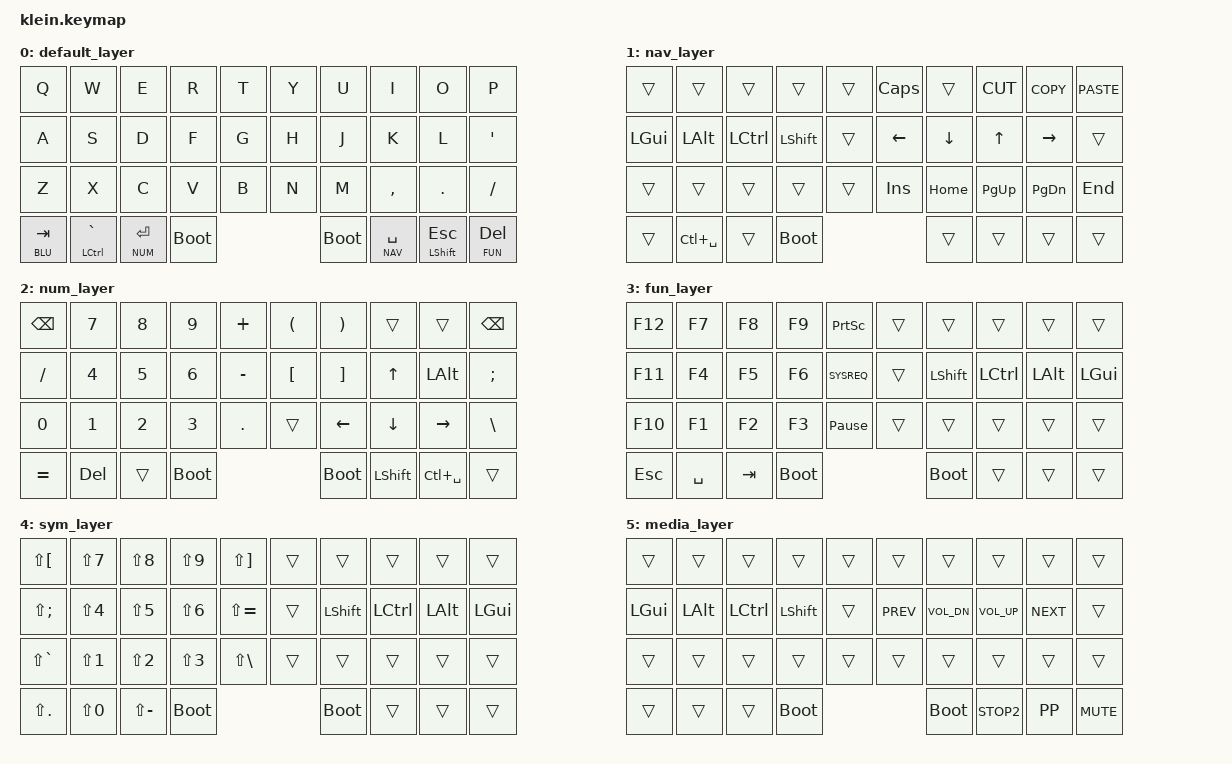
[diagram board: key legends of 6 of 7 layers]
/*
 * Copyright (c) 2020 The ZMK Contributors
 *
 * SPDX-License-Identifier: MIT
 */


#include <behaviors.dtsi>
#include <dt-bindings/zmk/keys.h>
#include <dt-bindings/zmk/bt.h>
#include <dt-bindings/zmk/outputs.h>

#define BASE 0
#define NAV  1
#define NUM  2
#define FUN  3
#define SYM  4
#define MEDIA  5
#define BLU 6

&mt {
  tapping-term-ms = <180>;
};


/ {
    keymap {
        compatible = "zmk,keymap";

        default_layer {
//          ------------------------------------------------------------------------------------------------------------
//          |  Q  |  W  |  E   |  R   |  T   |                                           |  Y   |  U    |  I    |  O   |   P   |
//          |  A  |  S  |  D   |  F   |  G   |                                           |  H   |  J    |  K    |  L   |   '   |
//          |  Z  |  X  |  C   |  V   |  B   |                                           |  N   |  M    |  ,    |  .   |   /   |
//                      | ESC  | SPC |  TAB | BOOTLOADER |                         | MUTE | RET | BKSP | DEL |

            bindings = <
&kp Q          &kp W          &kp E          &kp R          &kp T               &kp Y          &kp U          &kp I          &kp O          &kp P
&kp A          &kp S          &kp D          &kp F          &kp G               &kp H          &kp J            &kp K         &kp L          &kp SQT
&kp Z          &kp X          &kp C          &kp V          &kp B               &kp N          &kp M          &kp COMMA      &kp DOT        &kp FSLH
&lt BLU TAB &mt LCTRL GRAVE  &lt NUM ENTER &bootloader                                       &bootloader      &lt NAV SPACE  &mt LSHFT ESC  &lt FUN DEL
            >;
        sensor-bindings = <&inc_dec_kp C_VOL_DN C_VOL_UP &inc_dec_kp UP DOWN>;
        };

        nav_layer {

            bindings = <
&trans         &trans         &trans         &trans         &trans              &kp CAPSLOCK   &trans         &kp K_CUT      &kp K_COPY     &kp K_PASTE
&kp LGUI       &kp LALT       &kp LCTRL      &kp LSHFT      &trans              &kp LEFT       &kp DOWN       &kp UP         &kp RIGHT      &trans
&trans         &trans         &trans         &trans         &trans              &kp INSERT     &kp HOME       &kp PG_UP      &kp PG_DN      &kp END
&trans         &kp LC(SPACE)      &trans         &bootloader                                       &trans     &trans       &trans      &trans
            >;
        sensor-bindings = <&inc_dec_kp C_VOL_DN C_VOL_UP>;
        };

        num_layer {
            
            bindings = <
&kp BSPC       &kp N7         &kp N8         &kp N9         &kp PLUS            &kp LPAR       &kp RPAR       &trans         &trans         &kp BSPC
&kp FSLH       &kp N4         &kp N5         &kp N6         &kp MINUS           &kp LBKT       &kp RBKT       &kp UP         &kp LALT       &kp SEMI
&kp N0         &kp N1         &kp N2         &kp N3         &kp DOT             &trans         &kp LEFT       &kp DOWN       &kp RIGHT      &kp BSLH
&kp EQUAL      &kp DEL        &trans         &bootloader                                       &bootloader    &kp LSHFT      &kp LC(SPACE)         &trans
            >;
        sensor-bindings = <&inc_dec_kp C_VOL_DN C_VOL_UP &inc_dec_kp PG_UP PG_DN>;
        };

        fun_layer {
            
            bindings = <
&kp F12        &kp F7         &kp F8         &kp F9         &kp PSCRN           &trans         &trans         &trans         &trans         &trans
&kp F11        &kp F4         &kp F5         &kp F6         &kp SYSREQ          &trans         &kp LSHFT      &kp LCTRL      &kp LALT       &kp LGUI
&kp F10        &kp F1         &kp F2         &kp F3         &kp PAUSE_BREAK     &trans         &trans         &trans         &trans         &trans
&kp ESC        &kp SPACE      &kp TAB        &bootloader                                       &bootloader    &trans         &trans         &trans
            >;
        sensor-bindings = <&inc_dec_kp C_VOL_DN C_VOL_UP>;
        };

        sym_layer {
            
            bindings = <
&kp LS(LBKT)   &kp LS(N7)     &kp LS(N8)     &kp LS(N9)     &kp LS(RBKT)        &trans         &trans         &trans         &trans         &trans
&kp LS(SEMI)   &kp LS(N4)     &kp LS(N5)     &kp LS(N6)     &kp LS(EQUAL)       &trans         &kp LSHFT      &kp LCTRL      &kp LALT       &kp LGUI
&kp LS(GRAVE)  &kp LS(N1)     &kp LS(N2)     &kp LS(N3)     &kp LS(BSLH)        &trans         &trans         &trans         &trans         &trans
&kp LS(PERIOD) &kp LS(N0)     &kp LS(MINUS)  &bootloader                                       &bootloader    &trans         &trans         &trans
            >;
        sensor-bindings = <&inc_dec_kp C_VOL_DN C_VOL_UP>;
        };

        media_layer {
            
            bindings = <
&trans         &trans         &trans         &trans         &trans              &trans         &trans         &trans         &trans         &trans
&kp LGUI       &kp LALT       &kp LCTRL      &kp LSHFT      &trans              &kp K_PREV     &kp K_VOL_DN   &kp K_VOL_UP   &kp K_NEXT     &trans
&trans         &trans         &trans         &trans         &trans              &trans         &trans         &trans         &trans         &trans
&trans         &trans         &trans         &bootloader                                       &bootloader    &kp K_STOP2    &kp K_PP       &kp K_MUTE
            >;
        sensor-bindings = <&inc_dec_kp C_VOL_DN C_VOL_UP>;
        };

        blu_layer {
            
            bindings = <
&trans         &trans         &trans         &trans         &trans              &bt BT_CLR     &trans         &trans         &trans         &trans
&trans         &bt BT_SEL 3   &bt BT_SEL 4   &trans         &trans              &trans         &bt BT_PRV     &bt BT_NXT     &trans         &trans
&trans         &bt BT_SEL 0   &bt BT_SEL 1   &bt BT_SEL 2   &trans              &trans         &trans         &trans         &trans         &trans
&trans         &trans         &trans         &trans         &trans                             &trans         &trans         &trans         &trans
            >;
        sensor-bindings = <&inc_dec_kp C_VOL_DN C_VOL_UP>;
        };
    };
};
 
